VERSION ""

NS_ :

BS_:

BU_: BMS Third_Party_Device

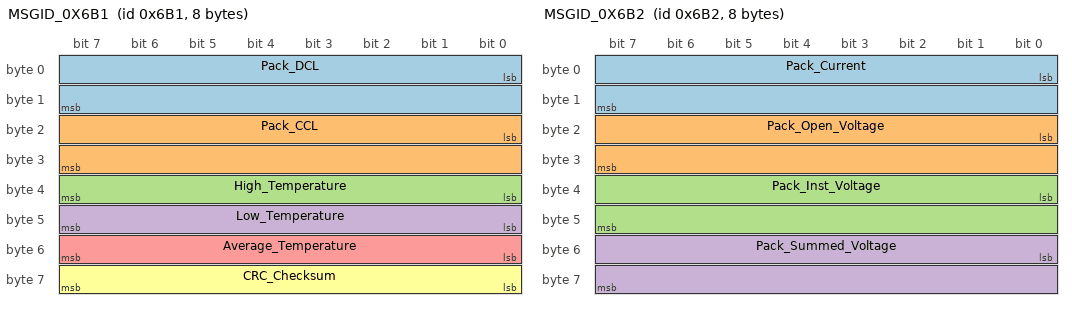
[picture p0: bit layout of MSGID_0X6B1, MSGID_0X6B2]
BO_ 1713 MSGID_0X6B1: 8 BMS
 SG_ Pack_DCL : 0|16@1+ (1.0,0) [0|0] "Amps"  Third_Party_Device
 SG_ Pack_CCL : 16|16@1+ (1.0,0) [0|0] "Amps"  Third_Party_Device
 SG_ High_Temperature : 39|8@0+ (1.0,0) [0|0] "Celsius"  Third_Party_Device
 SG_ Low_Temperature : 47|8@0+ (1.0,0) [0|0] "Celsius"  Third_Party_Device
 SG_ Average_Temperature : 55|8@0+ (1.0,0) [0|0] "Celsius"  Third_Party_Device
 SG_ CRC_Checksum : 63|8@0+ (1.0,1721) [0|0] ""  Third_Party_Device

BO_ 1714 MSGID_0X6B2: 8 BMS
 SG_ Pack_Current : 0|16@1- (0.1,0) [0|0] "Amps"  Third_Party_Device
 SG_ Pack_Open_Voltage : 16|16@1+ (0.1,0) [0|0] "Volts"  Third_Party_Device
 SG_ Pack_Inst_Voltage : 32|16@1+ (0.1,0) [0|0] "Volts"  Third_Party_Device
 SG_ Pack_Summed_Voltage : 48|16@1+ (0.01,0) [0|0] "Volts"  Third_Party_Device

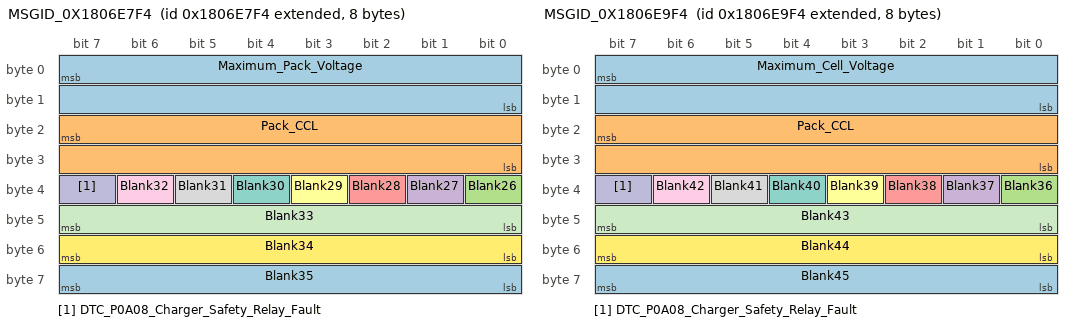
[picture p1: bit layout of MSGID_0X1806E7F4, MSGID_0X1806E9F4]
BO_ 2550589428 MSGID_0X1806E7F4: 8 BMS
 SG_ Maximum_Pack_Voltage : 7|16@0+ (0.1,0) [0|0] "Volts"  Third_Party_Device
 SG_ Pack_CCL : 23|16@0+ (0.1,0) [0|0] "Amps"  Third_Party_Device
 SG_ Blank26 : 32|1@1+ (1.0,0) [0|1] ""  Third_Party_Device
 SG_ Blank27 : 33|1@1+ (1.0,0) [0|1] ""  Third_Party_Device
 SG_ Blank28 : 34|1@1+ (1.0,0) [0|1] ""  Third_Party_Device
 SG_ Blank29 : 35|1@1+ (1.0,0) [0|1] ""  Third_Party_Device
 SG_ Blank30 : 36|1@1+ (1.0,0) [0|1] ""  Third_Party_Device
 SG_ Blank31 : 37|1@1+ (1.0,0) [0|1] ""  Third_Party_Device
 SG_ Blank32 : 38|1@1+ (1.0,0) [0|1] ""  Third_Party_Device
 SG_ DTC_P0A08_Charger_Safety_Relay_Fault : 39|1@1+ (1.0,0) [0|1] ""  Third_Party_Device
 SG_ Blank33 : 47|8@0+ (0.1,0) [0|0] ""  Third_Party_Device
 SG_ Blank34 : 55|8@0+ (1.0,0) [0|0] ""  Third_Party_Device
 SG_ Blank35 : 63|8@0+ (1.0,0) [0|0] ""  Third_Party_Device

BO_ 2550589940 MSGID_0X1806E9F4: 8 BMS
 SG_ Maximum_Cell_Voltage : 7|16@0+ (0.0016666666666666668,0) [0|0] "Volts"  Third_Party_Device
 SG_ Pack_CCL : 23|16@0+ (0.1,0) [0|0] "Amps"  Third_Party_Device
 SG_ Blank36 : 32|1@1+ (1.0,0) [0|1] ""  Third_Party_Device
 SG_ Blank37 : 33|1@1+ (1.0,0) [0|1] ""  Third_Party_Device
 SG_ Blank38 : 34|1@1+ (1.0,0) [0|1] ""  Third_Party_Device
 SG_ Blank39 : 35|1@1+ (1.0,0) [0|1] ""  Third_Party_Device
 SG_ Blank40 : 36|1@1+ (1.0,0) [0|1] ""  Third_Party_Device
 SG_ Blank41 : 37|1@1+ (1.0,0) [0|1] ""  Third_Party_Device
 SG_ Blank42 : 38|1@1+ (1.0,0) [0|1] ""  Third_Party_Device
 SG_ DTC_P0A08_Charger_Safety_Relay_Fault : 39|1@1+ (1.0,0) [0|1] ""  Third_Party_Device
 SG_ Blank43 : 47|8@0+ (1.0,0) [0|0] ""  Third_Party_Device
 SG_ Blank44 : 55|8@0+ (1.0,0) [0|0] ""  Third_Party_Device
 SG_ Blank45 : 63|8@0+ (1.0,0) [0|0] ""  Third_Party_Device

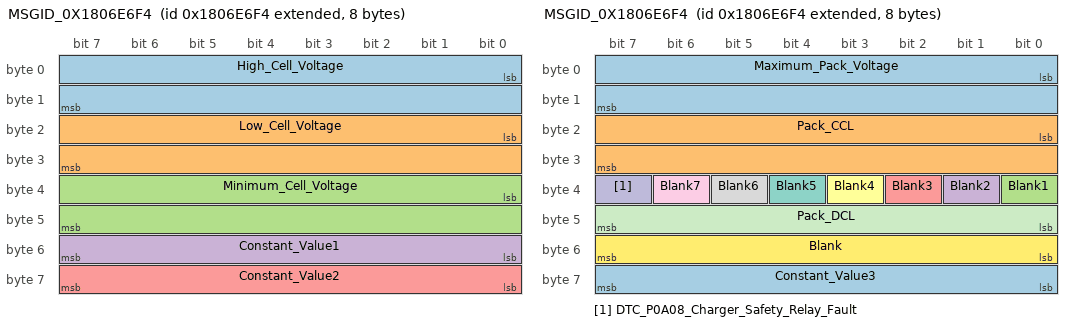
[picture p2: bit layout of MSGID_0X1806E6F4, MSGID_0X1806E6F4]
BO_ 2550589172 MSGID_0X1806E6F4: 8 BMS
 SG_ High_Cell_Voltage : 0|16@1+ (1.0E-4,0) [0|0] "Volts"  Third_Party_Device
 SG_ Low_Cell_Voltage : 16|16@1+ (1.0E-4,0) [0|0] "Volts"  Third_Party_Device
 SG_ Minimum_Cell_Voltage : 32|16@1+ (1.0E-4,0) [0|0] "Volts"  Third_Party_Device
 SG_ Constant_Value1 : 55|8@0+ (1.0,0) [0|0] ""  Third_Party_Device
 SG_ Constant_Value2 : 63|8@0+ (1.0,3) [3|3] ""  Third_Party_Device

BO_ 2550589172 MSGID_0X1806E6F4: 8 BMS
 SG_ Maximum_Pack_Voltage : 0|16@1+ (0.1,0) [0|0] "Volts"  Third_Party_Device
 SG_ Pack_CCL : 16|16@1+ (0.1,0) [0|0] "Amps"  Third_Party_Device
 SG_ Blank1 : 32|1@1+ (1.0,0) [0|1] ""  Third_Party_Device
 SG_ Blank2 : 33|1@1+ (1.0,0) [0|1] ""  Third_Party_Device
 SG_ Blank3 : 34|1@1+ (1.0,0) [0|1] ""  Third_Party_Device
 SG_ Blank4 : 35|1@1+ (1.0,0) [0|1] ""  Third_Party_Device
 SG_ Blank5 : 36|1@1+ (1.0,0) [0|1] ""  Third_Party_Device
 SG_ Blank6 : 37|1@1+ (1.0,0) [0|1] ""  Third_Party_Device
 SG_ Blank7 : 38|1@1+ (1.0,0) [0|1] ""  Third_Party_Device
 SG_ DTC_P0A08_Charger_Safety_Relay_Fault : 39|1@1+ (1.0,0) [0|1] ""  Third_Party_Device
 SG_ Pack_DCL : 47|8@0+ (0.1,0) [0|0] "Amps"  Third_Party_Device
 SG_ Blank : 55|8@0+ (1.0,0) [0|0] ""  Third_Party_Device
 SG_ Constant_Value3 : 63|8@0+ (1.0,1) [1|1] ""  Third_Party_Device

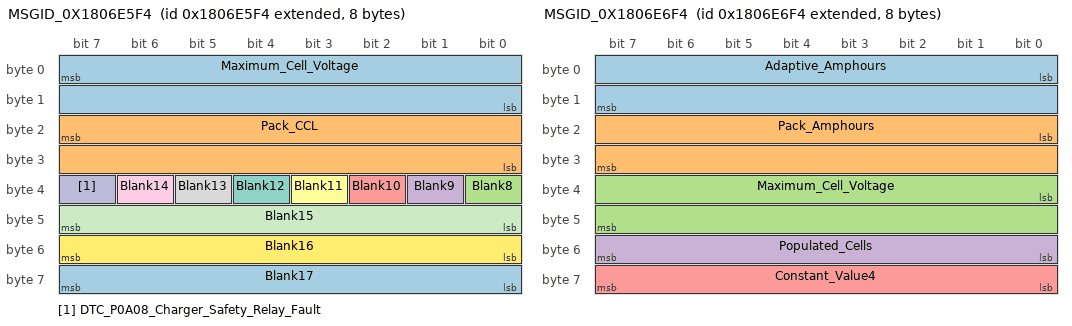
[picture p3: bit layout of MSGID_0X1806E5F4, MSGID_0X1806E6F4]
BO_ 2550588916 MSGID_0X1806E5F4: 8 BMS
 SG_ Maximum_Cell_Voltage : 7|16@0+ (0.0016666666666666668,0) [0|0] "Volts"  Third_Party_Device
 SG_ Pack_CCL : 23|16@0+ (0.1,0) [0|0] "Amps"  Third_Party_Device
 SG_ Blank8 : 32|1@1+ (1.0,0) [0|1] ""  Third_Party_Device
 SG_ Blank9 : 33|1@1+ (1.0,0) [0|1] ""  Third_Party_Device
 SG_ Blank10 : 34|1@1+ (1.0,0) [0|1] ""  Third_Party_Device
 SG_ Blank11 : 35|1@1+ (1.0,0) [0|1] ""  Third_Party_Device
 SG_ Blank12 : 36|1@1+ (1.0,0) [0|1] ""  Third_Party_Device
 SG_ Blank13 : 37|1@1+ (1.0,0) [0|1] ""  Third_Party_Device
 SG_ Blank14 : 38|1@1+ (1.0,0) [0|1] ""  Third_Party_Device
 SG_ DTC_P0A08_Charger_Safety_Relay_Fault : 39|1@1+ (1.0,0) [0|1] ""  Third_Party_Device
 SG_ Blank15 : 47|8@0+ (0.1,0) [0|0] ""  Third_Party_Device
 SG_ Blank16 : 55|8@0+ (1.0,0) [0|0] ""  Third_Party_Device
 SG_ Blank17 : 63|8@0+ (1.0,0) [0|0] ""  Third_Party_Device

BO_ 2550589172 MSGID_0X1806E6F4: 8 BMS
 SG_ Adaptive_Amphours : 0|16@1+ (1.666666666666667,0) [0|0] "Amphours"  Third_Party_Device
 SG_ Pack_Amphours : 16|16@1+ (0.010000000000000002,0) [0|0] "Amphours"  Third_Party_Device
 SG_ Maximum_Cell_Voltage : 32|16@1+ (1.0E-4,6) [0|0] "Volts"  Third_Party_Device
 SG_ Populated_Cells : 55|8@0+ (1.0,0) [0|0] "Num"  Third_Party_Device
 SG_ Constant_Value4 : 63|8@0+ (1.0,2) [2|2] ""  Third_Party_Device

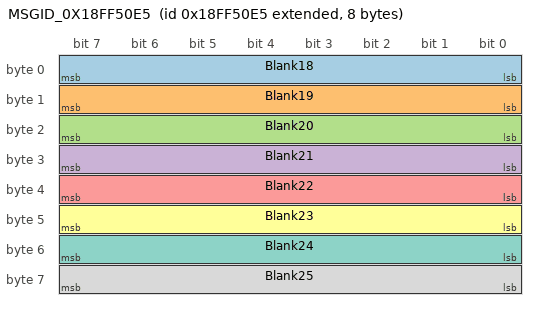
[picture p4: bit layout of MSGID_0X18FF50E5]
BO_ 2566869221 MSGID_0X18FF50E5: 8 Third_Party_Device
 SG_ Blank18 : 7|8@0+ (1.0,0) [0|0] ""  BMS
 SG_ Blank19 : 15|8@0+ (1.0,0) [0|0] ""  BMS
 SG_ Blank20 : 23|8@0+ (1.0,0) [0|0] ""  BMS
 SG_ Blank21 : 31|8@0+ (1.0,0) [0|0] ""  BMS
 SG_ Blank22 : 39|8@0+ (1.0,0) [0|0] ""  BMS
 SG_ Blank23 : 47|8@0+ (1.0,0) [0|0] ""  BMS
 SG_ Blank24 : 55|8@0+ (1.0,0) [0|0] ""  BMS
 SG_ Blank25 : 63|8@0+ (1.0,0) [0|0] ""  BMS

CM_ BO_ 1713 "This ID Transmits at 104 ms.";
CM_ BO_ 1714 "This ID Transmits at 48 ms.";
CM_ BO_ 2550589428 "This ID Transmits at 808 ms.";
CM_ BO_ 2550589940 "This ID Transmits at 808 ms.";
CM_ BO_ 2550589172 "This ID Transmits at 1000 ms.";
CM_ BO_ 2550589172 "This ID Transmits at 1000 ms.";
CM_ BO_ 2550588916 "This ID Transmits at 808 ms.";
CM_ BO_ 2550589172 "This ID Transmits at 1000 ms.";
